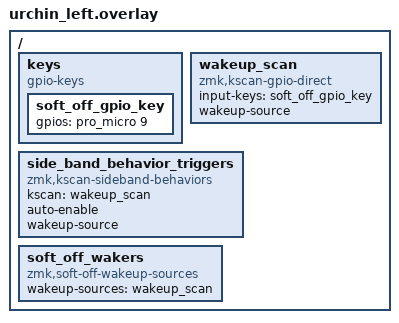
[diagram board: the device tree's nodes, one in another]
#include <dt-bindings/gpio/gpio.h>

/ {
    keys {
        compatible = "gpio-keys";
        soft_off_gpio_key: soft_off_gpio_key {
            gpios = <&pro_micro 9 (GPIO_ACTIVE_HIGH | GPIO_PULL_DOWN)>;
        };
    };

    wakeup_scan: wakeup_scan {
        compatible = "zmk,kscan-gpio-direct";
        input-keys = <&soft_off_gpio_key>;
        wakeup-source;
    };

    side_band_behavior_triggers: side_band_behavior_triggers {
        compatible = "zmk,kscan-sideband-behaviors";
        kscan = <&wakeup_scan>;
        auto-enable;
        wakeup-source;
    };

    soft_off_wakers {
        compatible = "zmk,soft-off-wakeup-sources";
        wakeup-sources = <&wakeup_scan>;
    };
};
